# CY8C4A45LQI_483 register map
File version: 0.1
Registers are 32-bit, read-write, no defined reset value unless marked. A register's access mark holds for its fields unless they carry their own. Offsets are from the block's base; [hi:lo] are bit positions; {n}, {i} and the like mark numbered series; 'fields as' and 'values as' point back to an identical list.

## engine_sensor_adc_UABH_B
Base 0x00000000
Same registers: engine_sensor_adc_UABH_A 0x00000000
0x40340000 UAB_UAB_CTRL — Global UAB control
  [31] ENABLED — - 0: UAB IP disabled (put analog in power down, open all switches)?- 1: UAB IP enabled
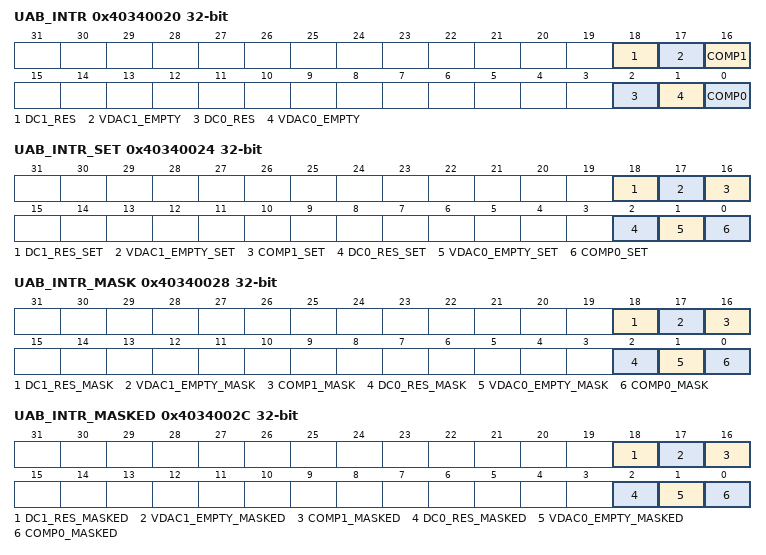
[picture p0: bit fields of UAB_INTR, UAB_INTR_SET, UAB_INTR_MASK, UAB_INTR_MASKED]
0x40340020 UAB_INTR — Interrupt request register
  [18] DC1_RES — Decimator 1 Result Interrupt: hardware sets this interrupt when Decimator 1 writes a new result value in DC1_RES register. Write with '1' to clear bit.
  [17] VDAC1_EMPTY — VDAC 1 Interrupt: hardware sets this interrupt when VDAC 1 next value field is empty. Write with '1' to clear bit.
  [16] COMP1 — Comparator 1 Interrupt: hardware sets this interrupt when comparator 1 triggers. Write with '1' to clear bit.
  [2] DC0_RES — Decimator 0 Result Interrupt: hardware sets this interrupt when Decimator 0 writes a new result value in DC0_RES register. Write with '1' to clear bit.
  [1] VDAC0_EMPTY — VDAC 0 Interrupt: hardware sets this interrupt when VDAC 0 next value field is empty. Write with '1' to clear bit.
  [0] COMP0 — Comparator 0 Interrupt: hardware sets this interrupt when comparator 0 triggers. Write with '1' to clear bit.
0x40340024 UAB_INTR_SET — Interrupt request set register
  [18] DC1_RES_SET — Write with '1' to set corresponding bit in interrupt request register.
  [17] VDAC1_EMPTY_SET — Write with '1' to set corresponding bit in interrupt request register.
  [16] COMP1_SET — Write with '1' to set corresponding bit in interrupt request register.
  [2] DC0_RES_SET — Write with '1' to set corresponding bit in interrupt request register.
  [1] VDAC0_EMPTY_SET — Write with '1' to set corresponding bit in interrupt request register.
  [0] COMP0_SET — Write with '1' to set corresponding bit in interrupt request register.
0x40340028 UAB_INTR_MASK — Interrupt request mask
  [18] DC1_RES_MASK — Mask bit for corresponding bit in interrupt request register.
  [17] VDAC1_EMPTY_MASK — Mask bit for corresponding bit in interrupt request register.
  [16] COMP1_MASK — Mask bit for corresponding bit in interrupt request register.
  [2] DC0_RES_MASK — Mask bit for corresponding bit in interrupt request register.
  [1] VDAC0_EMPTY_MASK — Mask bit for corresponding bit in interrupt request register.
  [0] COMP0_MASK — Mask bit for corresponding bit in interrupt request register.
0x4034002C UAB_INTR_MASKED — Interrupt request masked
  [18] DC1_RES_MASKED ro — Logical and of corresponding request and mask bits.
  [17] VDAC1_EMPTY_MASKED ro — Logical and of corresponding request and mask bits.
  [16] COMP1_MASKED ro — Logical and of corresponding request and mask bits.
  [2] DC0_RES_MASKED ro — Logical and of corresponding request and mask bits.
  [1] VDAC0_EMPTY_MASKED ro — Logical and of corresponding request and mask bits.
  [0] COMP0_MASKED ro — Logical and of corresponding request and mask bits.
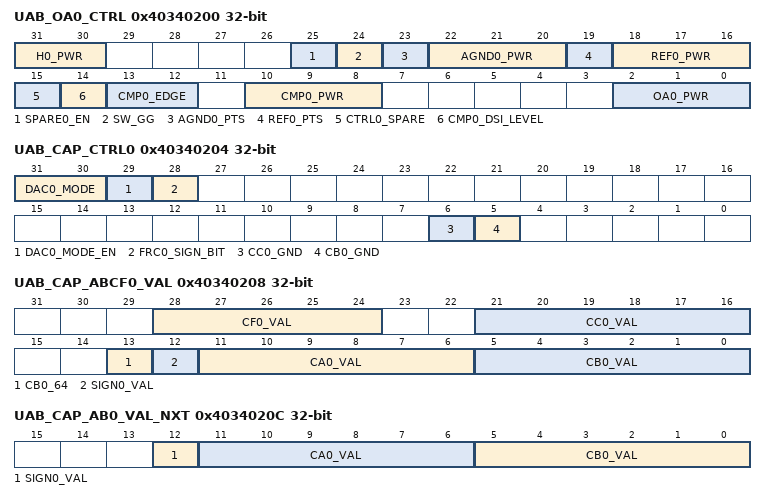
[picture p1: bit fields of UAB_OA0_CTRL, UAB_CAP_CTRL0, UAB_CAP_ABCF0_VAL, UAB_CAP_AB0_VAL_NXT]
0x40340200 UAB_OA0_CTRL — Opamp, comparator, buffer controls
  [31:30] H0_PWR — UAB Half, power profile
    0=NORMAL (Normal, for normal analog clock speeds); 1=ULTRA_LOW (Ultra low power, only allowed for lower analog clock speeds); 2=ULTRA_HIGH (Ultra high performance, for higher analog clock speeds (also ultra high power))
  [25] SPARE0_EN — 1 - Enable spare reference
  [24] SW_GG — Connect outputs of Agnd0 and Agnd1 buffer, one buffer must be off.?This is to drive both UAB halves with the same buffer, so both halves get the same offset noise.
  [23] AGND0_PTS — 1 - Pull Agnd0 buffer output to VDDA
  [22:20] AGND0_PWR — Agnd0 buffer power level
  [19] REF0_PTS — 1- Pull the Reference0 buffer output to VDDA
  [18:16] REF0_PWR — Reference0 buffer power level
  [15] CTRL0_SPARE — Spare bit
  [14] CMP0_DSI_LEVEL — Comparator0 trigger out level : 0=pulse, 1=level
  [13:12] CMP0_EDGE — Comparator0 edge detect for interrupt and trigger
    0=DISABLE (Disabled, no interrupts will be detected); 1=RISING (Rising edge); 2=FALLING (Falling edge); 3=BOTH (Both rising and falling edges)
  [10:8] CMP0_PWR — Comparator0 power level
  [2:0] OA0_PWR — Opamp0 power level
0x40340204 UAB_CAP_CTRL0 — Capacitance controls
  [31:30] DAC0_MODE — DAC mode, this determines the AB Cap Value decoding
    0=UNSIGNED12 (Off or Unsigned 12-bit VDAC, i.e. no AB Cap value decoding.?SIGN1_VAL can be used as Firmware controlled modbit (e.g. to invert the Voltage for a Sign + Magnitude VDAC)); 1=VIRT_SIGNED12 (Virtual signed 12-bits' VDAC. AB Cap value decoding: ?add 0x800 to the 12-bit AB Cap Value (=invert MSB), to convert the lowest signed number 0x800 to the lowest unsigned number 0x000. This is the same as the SAR handles 12-bit 'virtual' signed numbers.); 2=SIGNED13 (Signed 13-bit twos complement. AB Cap value decoding: ?for negative values (SIGN0_VAL=1) the AB Cap values are inverted, the 64th B cap unit is enabled and the Voltage should be inverted.?- Voltage inversion only works if the right clocking waveforms, switch settings and reference voltages are used.?- Enabling the 64th B cap unit adds 1 so that only a AB Cap value inversion is needed to create a true twos complement.)
  [29] DAC0_MODE_EN — 0: SIGN0_VAL can be programmed to be a modbit source?1: SIGN0_VAL is a dedicated sign bit (FW modbit source tied to 0)
  [28] FRC0_SIGN_BIT — Forces the sign bit to be 1 in DAC mode. This is used to achieve ?0 - AGND0 range for unsigned numbers using DAC mode 2
  [6] CC0_GND — Ground unused caps of CC0 array?0: leave unused caps floating?1: ground unused caps (typical when attentuation Cap is used)
  [5] CB0_GND — Ground unused caps of CB0 array?0: leave unused caps floating?1: ground unused caps (typical when attentuation Cap is used, e.g. for VDAC use-case)
0x40340208 UAB_CAP_ABCF0_VAL — Capacitance values for CA0, CB0, CC0 and CF0
  [28:24] CF0_VAL — Cap F0 Value [2..64 is the range in steps of 2]
  [21:16] CC0_VAL — Cap C0 Value
  [13] CB0_64 — Enable 64th Cap of CB0 array. In DAC mode the FW setting is overridden by the hardware based on DAC_MODE setting.?1 - Enables the 64th cap. This will also set CB0_val[5:0] to be 6'h3F
  [12] SIGN0_VAL — Sign bit Value, when used in DAC_MODE, otherwise Firmware modbit.?In DAC_MODE the modbit should be used to invert the voltage on the AB Caps for the negative DAC values.
  [11:6] CA0_VAL — Cap A0 Value, in DAC_MODE 1 and 2 this value is decoded
  [5:0] CB0_VAL — Cap B0 Value, in DAC_MODE 1 and 2 this value is decoded
0x4034020C UAB_CAP_AB0_VAL_NXT — Next capacitance values for CA0 and CB0
  [12] SIGN0_VAL — Sign bit Value
  [11:6] CA0_VAL — Cap A0 Value
  [5:0] CB0_VAL — Cap B0 Value
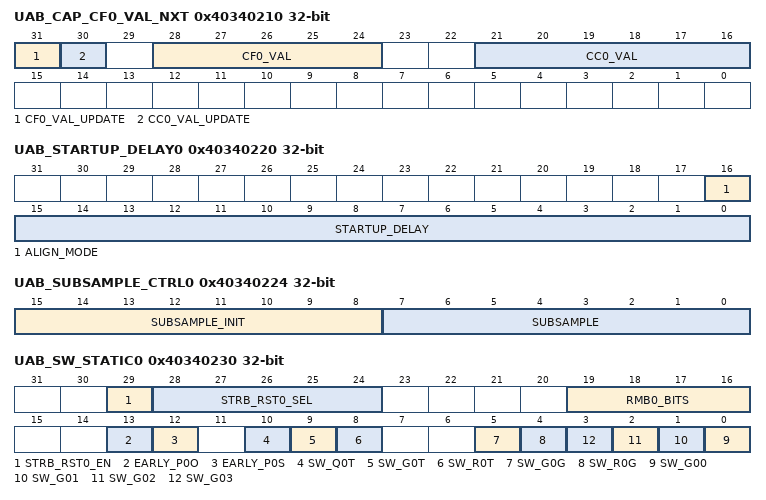
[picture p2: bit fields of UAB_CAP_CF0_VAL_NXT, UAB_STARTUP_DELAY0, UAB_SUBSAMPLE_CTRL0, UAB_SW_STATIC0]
0x40340210 UAB_CAP_CF0_VAL_NXT — Next capacitance values for CC0 and CF0
  [31] CF0_VAL_UPDATE — 1 - Update the CF0 cap value with CAP_CF0_VAL_NXT.CF0_VAL
  [30] CC0_VAL_UPDATE — 1 - Update the CC0 cap value with CAP_CC0_VAL_NXT.CC0_VAL
  [28:24] CF0_VAL — Cap F0 Value
  [21:16] CC0_VAL — Cap C0 Value
0x40340220 UAB_STARTUP_DELAY0 — Startup delay
  [16] ALIGN_MODE — 0 - STARTUP_DELAY is number of clk_hf clocks to delay the UAB clock after a SAR Trigger for UAB-SAR alignment in scheduled mode?1 - STARTUP_DELAY is number of clk_hf clocks to delay UAB trigger to SAR for UAB-SAR alignment in unscheduled mode
  [15:0] STARTUP_DELAY — Startup delay to synchronize the UAB-SAR interface. The usage and meaning of this field depends on the value of the ALIGN_MODE bit (below). A value of 0 disables this function.
0x40340224 UAB_SUBSAMPLE_CTRL0 — Subsample control
  [15:8] SUBSAMPLE_INIT — Initial value of the subsampling down counter. Before this UAB half is running the firmware can write to this field the initial value of the subsample down counter. It is recommend that the following is true for the initial value SUBSAMPLE_INIT<=SUBSAMPLE, however this is not a requirement. Writing a bigger value can be used to postpone the very first Valid output.
  [7:0] SUBSAMPLE — Subsampling: suppress Valid output during the first SUBSAMPLE analog clock periods. Only allow Valid output in the last of the SUBSAMPLE+1 analog clock periods.?A value of 0 will not suppress Valid output.
0x40340230 UAB_SW_STATIC0 — Static switches for half 0 of the UAB
  [29] STRB_RST0_EN — Enable VDAC strobe or UAB analog-reset:?0: Use selected source as VDAC strobe for next CA0 and CB0 values?1: Use selected source as Analog-reset (discharge all Caps)
  [28:24] STRB_RST0_SEL — Select source either for VDAC strobe or analog-reset to discharge all Caps (Delsig Modulator use-case)?0 = Decimator0 half 0 analog-reset output?1 = Decimator0 half 1 analog-reset output?2 = Decimator1 half 0 analog-reset output?3 = Decimator1 half 1 analog-reset output?4 = Decimator2 half 0 analog-reset output?5 = Decimator2 half 1 analog-reset output?6 = Decimator3 half 0 analog-reset output?7 = Decimator3 half 1 analog-reset output?8-31 = generic trigger input 0-23?For PASS4B only values 0-1 and 8-13 are legal.
  [19:16] RMB0_BITS — Risk mitigation bits (To be defined if they are used)
  [13] EARLY_P0O — OUT0 to VOUT0 switch timing: 0=Regular, 1=Early
  [12] EARLY_P0S — OUT0 to Sum0 switch timing: 0=Regular, 1=Early
  [10] SW_Q0T — OUT1 to cmp0.vminus (Threshold)
  [9] SW_G0T — AGND0 to cmp0.vminus (Threshold)
  [8] SW_R0T — REF0 to cmp0.vminus (Threshold)
  [5] SW_G0G — AGND0 to OA0.vplus (AG0)
  [4] SW_R0G — REF0 to OA0.vplus (AG0)
  [n] SW_G{n:02} (n=0..3) — VIN{n:02} to OA0.vplus (AG0)
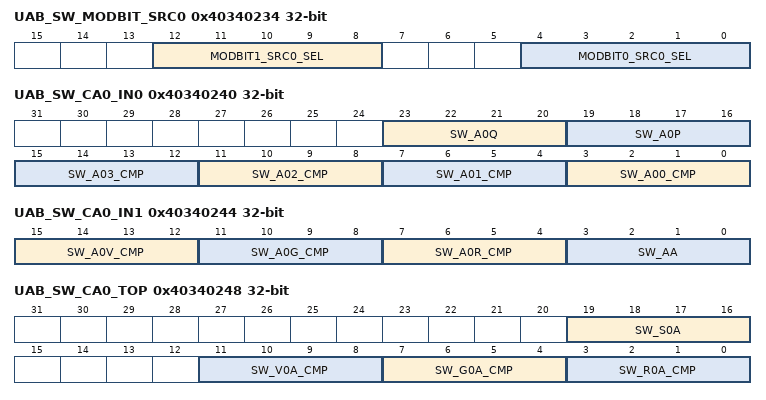
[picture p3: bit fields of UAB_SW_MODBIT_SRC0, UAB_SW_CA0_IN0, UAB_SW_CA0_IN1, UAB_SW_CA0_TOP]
0x40340234 UAB_SW_MODBIT_SRC0 — Select source of Modbit for A,B and C branches of half 0
  [12:8] MODBIT1_SRC0_SEL — Select source of modbit for C branch?0=UAB0 half 0 comparator output?1=UAB0 half 1 comparator output?2=UAB1 half 0 comparator output?3=UAB1 half 1 comparator output?4=UAB2 half 0 comparator output?5=UAB2 half 1 comparator output?6=UAB3 half 0 comparator output?7=UAB3 half 1 comparator output?8-30 = generic trigger inputs 0-22?31=SIGN0_VAL, also used as Firmware modbit. ?For PASS4B only values 0-1 and 8-13 and 31 are legal.
  [4:0] MODBIT0_SRC0_SEL — Select source of modbit for A & B branches?0=UAB0 half 0 comparator output?1=UAB0 half 1 comparator output?2=UAB1 half 0 comparator output?3=UAB1 half 1 comparator output?4=UAB2 half 0 comparator output?5=UAB2 half 1 comparator output?6=UAB3 half 0 comparator output?7=UAB3 half 1 comparator output?8-30 = generic trigger inputs 0-22?31=SIGN0_VAL, also used as Firmware modbit. ?For PASS4B only values 0-1 and 8-13 and 31 are legal.
0x40340240 UAB_SW_CA0_IN0 — Cap A0 input switches set 0
  [23:20] SW_A0Q — OUT1 to Cap A0 input
  [19:16] SW_A0P — OUT0 to Cap A0 input
  [4n+3:4n] SW_A{n:02}_CMP (n=0..3) — VIN{n:02} to Cap A0 input, allows for modbit control
0x40340244 UAB_SW_CA0_IN1 — Cap A0 input switches set 1
  [15:12] SW_A0V_CMP — VSS to Cap A0 input, allows for modbit control
  [11:8] SW_A0G_CMP — AGND0 to Cap A0 input, allows for modbit control
  [7:4] SW_A0R_CMP — REF0 to Cap A0 input, allows for modbit control
  [3:0] SW_AA — Cap A0 input to Cap A1 input?(Note: In the UAB design this is the called AM switch)
0x40340248 UAB_SW_CA0_TOP — Cap A0 top plate switches
  [19:16] SW_S0A — Cap A0 top plate to SUM0
  [11:8] SW_V0A_CMP — Cap A0 top plate to VSS, allows for modbit control
  [7:4] SW_G0A_CMP — Cap A0 top plate to AGND0, allows for modbit control
  [3:0] SW_R0A_CMP — Cap A0 top plate to REF0, allows for modbit control
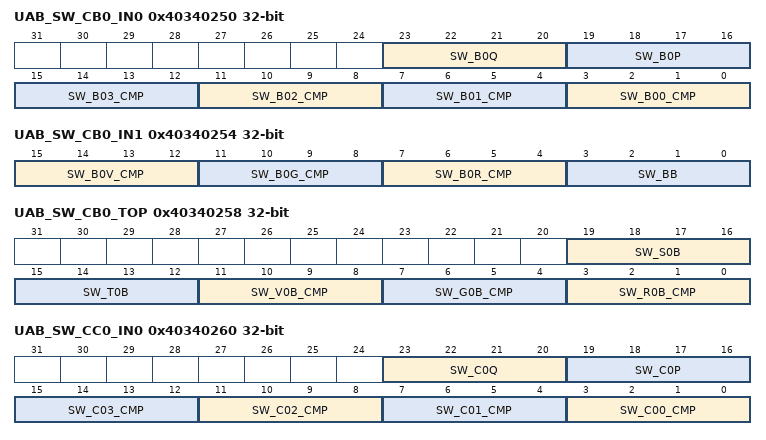
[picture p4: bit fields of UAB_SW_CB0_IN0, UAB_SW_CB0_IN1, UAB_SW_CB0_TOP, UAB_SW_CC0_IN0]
0x40340250 UAB_SW_CB0_IN0 — Cap B0 input switches set 0
  [23:20] SW_B0Q — OUT1 to Cap B0 input
  [19:16] SW_B0P — OUT0 to Cap B0 input
  [4n+3:4n] SW_B{n:02}_CMP (n=0..3) — VIN{n:02} to Cap B0 input, allows for modbit control
0x40340254 UAB_SW_CB0_IN1 — Cap B0 input switches set 1
  [15:12] SW_B0V_CMP — VSS to Cap B0 input, allows for modbit control
  [11:8] SW_B0G_CMP — AGND0 to Cap B0 input, allows for modbit control
  [7:4] SW_B0R_CMP — REF0 to Cap B0 input, allows for modbit control
  [3:0] SW_BB — Cap B0 input to Cap B1 input?(Note: In the UAB design this is called the BM switch)
0x40340258 UAB_SW_CB0_TOP — Cap A0 top plate switches
  [19:16] SW_S0B — Cap B0 top plate to SUM0
  [15:12] SW_T0B — Cap B0 top plate Trim/Attenuation bypass
  [11:8] SW_V0B_CMP — Cap B0 top plate to VSS, allows for modbit control
  [7:4] SW_G0B_CMP — Cap B0 top plate to AGND0, allows for modbit control
  [3:0] SW_R0B_CMP — Cap B0 top plate to REF0, allows for modbit control
0x40340260 UAB_SW_CC0_IN0 — Cap C0 input switches set 0
  [23:20] SW_C0Q — OUT1 to Cap C0 input
  [19:16] SW_C0P — OUT0 to Cap C0 input
  [4n+3:4n] SW_C{n:02}_CMP (n=0..3) — VIN{n:02} to Cap C0 input, allows for modbit control
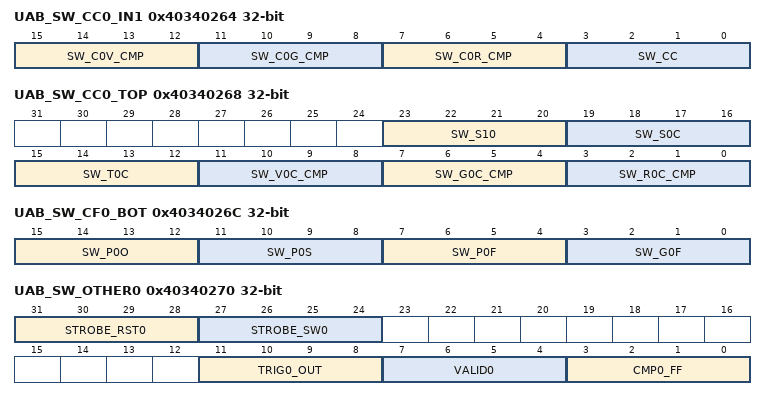
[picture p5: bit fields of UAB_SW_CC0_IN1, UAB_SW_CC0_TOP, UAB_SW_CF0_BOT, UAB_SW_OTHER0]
0x40340264 UAB_SW_CC0_IN1 — Cap C0 input switches set 1
  [15:12] SW_C0V_CMP — VSS to Cap C0 input, allows for modbit control
  [11:8] SW_C0G_CMP — AGND0 to Cap C0 input, allows for modbit control
  [7:4] SW_C0R_CMP — REF0 to Cap C0 input, allows for modbit control
  [3:0] SW_CC — Cap C0 input to Cap C1 input?(Note: In the UAB design this is called the CM switch)
0x40340268 UAB_SW_CC0_TOP — Cap A0 top plate switches
  [23:20] SW_S10 — Cap C0 top plate to SUM1
  [19:16] SW_S0C — Cap C0 top plate to SUM0
  [15:12] SW_T0C — Cap C0 top plate Trim/Attenuation bypass
  [11:8] SW_V0C_CMP — Cap C0 top plate to VSS, allows for modbit control
  [7:4] SW_G0C_CMP — Cap C0 top plate to AGND0, allows for modbit control
  [3:0] SW_R0C_CMP — Cap C0 top plate to REF0, allows for modbit control
0x4034026C UAB_SW_CF0_BOT — Cap F0 bottom plate and output switches
  [15:12] SW_P0O — OUT0 to VOUT0
  [11:8] SW_P0S — Cap F bypass, OUT0 to SUM0
  [7:4] SW_P0F — Cap F0 bottom plate to OUT0
  [3:0] SW_G0F — Cap F0 bottom plate to AGND0
0x40340270 UAB_SW_OTHER0 — Other clocked controls
  [31:28] STROBE_RST0 — Use the positive edge of the selected clocking waveform to synchronize: ? STRB_RST0_EN=0: Capacitor Value update (Capacitor Strobe)? STRB_RST0_EN=1: UAB analog-reset update?Set to 0 to disable both functions. Result undefined for value 15.
  [27:24] STROBE_SW0 — Strobe for dsi_sw_ctrl (modbit) update, dsi_sw_ctrl updates in sync with posedge of this wave. To disable set to 0. To enable update anytime use 15.
  [11:8] TRIG0_OUT — Trigger output (for other UABs or SAR)
  [7:4] VALID0 — Valid0, output flag to indicated that VOUT0 is valid. The Valid output can be suppressed due to sub-sampling. Note that when sub-sampling is used this clocking waveform is used to decrement the counter (decrement is aligned with the positive edge of this clocking waveform).
  [3:0] CMP0_FF — Clock for Flip-Flop after Comparator 0
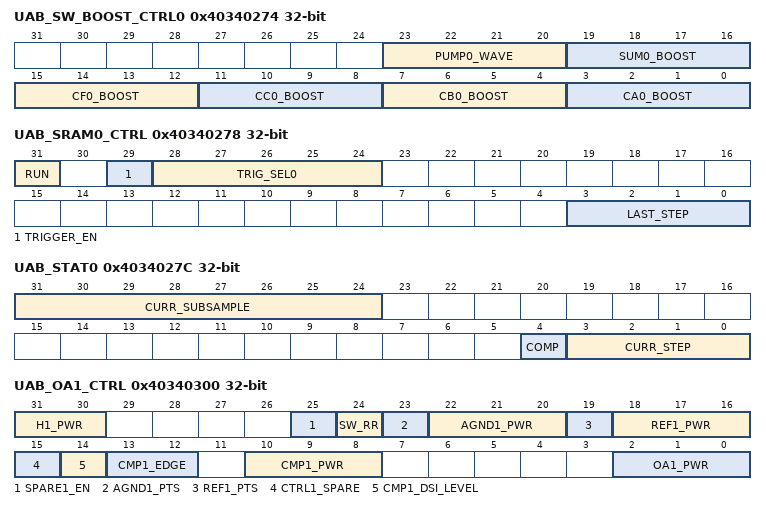
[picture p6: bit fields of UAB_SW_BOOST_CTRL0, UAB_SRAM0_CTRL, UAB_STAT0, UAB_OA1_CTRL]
0x40340274 UAB_SW_BOOST_CTRL0 — Bootstrap clock control
  [23:20] PUMP0_WAVE — Clock for pump in half0
  [19:16] SUM0_BOOST — Clock for boot strap master in Summing node branch
  [15:12] CF0_BOOST — Clock for boot strap master in F branch
  [11:8] CC0_BOOST — Clock for boot strap master in C branch
  [7:4] CB0_BOOST — Clock for boot strap master in B branch
  [3:0] CA0_BOOST — Clock for boot strap master in A branch
0x40340278 UAB_SRAM0_CTRL — SRAM programmed size
  [31] RUN — Set to start executing the waveform (may need to wait for a trigger). Clear to stop this UAB half. When RUN=0 all dynamic switches are forced open.
  [29] TRIGGER_EN — Enable input trigger:?0: Ignore triggers, start running immediately after setting RUN bit?1: After RUN bit is set wait for a positive edge on the selected trigger input
  [28:24] TRIG_SEL0 — input Trigger select?0=UAB0 half 0 trigger output?1=UAB0 half 1 trigger output?2=UAB1 half 0 trigger output?3=UAB1 half 1 trigger output?4=UAB2 half 0 trigger output?5=UAB2 half 1 trigger output?6=UAB3 half 0 trigger output?7=UAB3 half 1 trigger output?8-30 = generic trigger inputs 0-22?31=SAR trigger output?For PASS4B only values 0-1 and 8-13 and 31 are legal.
  [3:0] LAST_STEP — Last step of wave programmed in the SRAM
0x4034027C UAB_STAT0 — Status Current SRAM counter and comparator
  [31:24] CURR_SUBSAMPLE ro — Current value of the subsampling down counter. The Valid is suppressed when SUBSAMPLE_CUR!=0.
  [4] COMP ro — Current comparator status
  [3:0] CURR_STEP ro — Current step executed from the SRAM
{0x40340280+4i} UAB_SRAM{i:02} (i=0..9) — Waveform SRAM for half 0 of the UAB
  [15:0] WAVE_STEP — one step of the clocking waveform sequence
0x403402A8 UAB_SRAM010 — Waveform SRAM for half 0 of the UAB
  [15:0] WAVE_STEP — one step of the clocking waveform sequence
0x403402AC UAB_SRAM011 — Waveform SRAM for half 0 of the UAB
  [15:0] WAVE_STEP — one step of the clocking waveform sequence
0x403402B0 UAB_SRAM012 — Waveform SRAM for half 0 of the UAB
  [15:0] WAVE_STEP — one step of the clocking waveform sequence
0x403402B4 UAB_SRAM013 — Waveform SRAM for half 0 of the UAB
  [15:0] WAVE_STEP — one step of the clocking waveform sequence
0x403402B8 UAB_SRAM014 — Waveform SRAM for half 0 of the UAB
  [15:0] WAVE_STEP — one step of the clocking waveform sequence
0x403402BC UAB_SRAM015 — Waveform SRAM for half 0 of the UAB
  [15:0] WAVE_STEP — one step of the clocking waveform sequence
0x40340300 UAB_OA1_CTRL — Opamp, comparator, buffer controls
  [31:30] H1_PWR — UAB Half, power profile
    values as UAB_OA0_CTRL.H0_PWR
  [25] SPARE1_EN — 1 - Enable the spare reference
  [24] SW_RR — Connect outputs of Reference0 and Reference1 buffer, one buffer must be off.?This is to drive both UAB halves with the same buffer, so both halves get the same offset noise.
  [23] AGND1_PTS — 1- Pull the Agnd1 buffer output to VDDA
  [22:20] AGND1_PWR — Agnd1 buffer power
  [19] REF1_PTS — 1- Pull the Reference1 buffer output to VDDA
  [18:16] REF1_PWR — Reference1 buffer power
  [15] CTRL1_SPARE — Spare bit
  [14] CMP1_DSI_LEVEL — Comparator trigger out level : 0=pulse, 1=level
  [13:12] CMP1_EDGE — Comparator1 edge detect for interrupt and trigger
    values as UAB_OA0_CTRL.CMP0_EDGE
  [10:8] CMP1_PWR — Comparator1 power level
  [2:0] OA1_PWR — Opamp1 power level
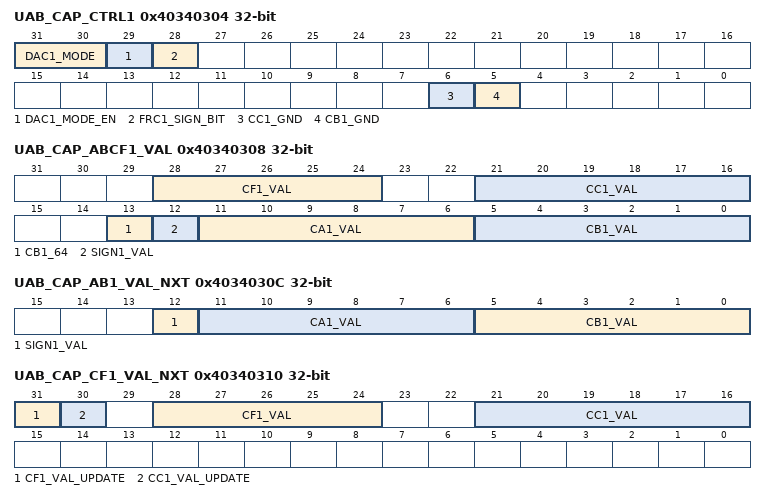
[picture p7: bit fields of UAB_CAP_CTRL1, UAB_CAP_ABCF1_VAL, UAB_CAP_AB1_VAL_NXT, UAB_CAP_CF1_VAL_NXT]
0x40340304 UAB_CAP_CTRL1 — Capacitance controls
  [31:30] DAC1_MODE — DAC mode, this determines the AB Cap Value decoding
    0=UNSIGNED12 (Off or Unsigned 12-bit VDAC, i.e. no AB Cap value decoding.?SIGN1_VAL can be used as Firmware controlled modbit (e.g. to invert the Voltage for a Sign + Magnitude VDAC)); 1=VIRT_SIGNED12 (Virtual signed 12-bits' VDAC. AB Cap value decoding: ?add 0x800 to the 12-bit AB Cap Value (=invert MSB), to convert the lowest signed number 0x800 to the lowest unsigned number 0x000. This is the same as the SAR handles 12-bit 'virtual' signed numbers.); 2=SIGNED13 (Signed 13-bit twos complement. AB Cap value decoding: ?for negative values (SIGN1_VAL=1) the AB Cap values are inverted, the 64th B cap unit is enabled and the Voltage should be inverted.?- Voltage inversion only works if the right clocking waveforms, switch settings and reference voltages are used.?- Enabling the 64th B cap unit adds 1 so that only a AB Cap value inversion is needed to create a true twos complement. .)
  [29] DAC1_MODE_EN — 1: SIGN1_VAL is dedicated sign bit (FW modbit source tied to 0) 0: SIGN1_VAL can be programmed to be a modbit source
  [28] FRC1_SIGN_BIT — Forces the sign bit to be 1 in DAC mode. This is used to achieve ?0 - AGND1 range for unsigned numbers using DAC mode 2
  [6] CC1_GND — Ground unused caps of CC1 array?0: leave unused caps floating?1: ground unused caps (typical when attentuation Cap is used)
  [5] CB1_GND — Ground unused caps of CB1 array?0: leave unused caps floating?1: ground unused caps (typical when attentuation Cap is used, e.g. for VDAC use-case)
0x40340308 UAB_CAP_ABCF1_VAL — Capacitance values for CA1, CB1, CC1 and CF1
  [28:24] CF1_VAL — Cap F1 Value
  [21:16] CC1_VAL — Cap C1 Value
  [13] CB1_64 — Enable 64th Cap of CB1 array. In DAC mode the FW setting is overridden by the hardware based on DAC_MODE setting. 1 - Enables the 64th cap. This will also set CB1_val[5:0] to be 6'h3F
  [12] SIGN1_VAL — Sign bit Value, when used in DAC_MODE, otherwise Firmware modbit.?In DAC_MODE the modbit should be used to invert the voltage on the AB Caps for the negative DAC values.
  [11:6] CA1_VAL — Cap A1 Value, in DAC_MODE 1 and 2 this value is decoded
  [5:0] CB1_VAL — Cap B1 Value, in DAC_MODE 1 and 2 this value is decoded
0x4034030C UAB_CAP_AB1_VAL_NXT — Next capacitance values for CA1 and CB1
  [12] SIGN1_VAL — Sign bit Value
  [11:6] CA1_VAL — Cap A1 Value
  [5:0] CB1_VAL — Cap B1 Value
0x40340310 UAB_CAP_CF1_VAL_NXT — Next capacitance values for CC1 and CF1
  [31] CF1_VAL_UPDATE — 1 - Update the CF1 cap value with CAP_CF1_VAL_NXT.CF1_VAL
  [30] CC1_VAL_UPDATE — 1 - Update the CC1 cap value with CAP_CC1_VAL_NXT.CC1_VAL
  [28:24] CF1_VAL — Cap F1 Value
  [21:16] CC1_VAL — Cap C1 Value
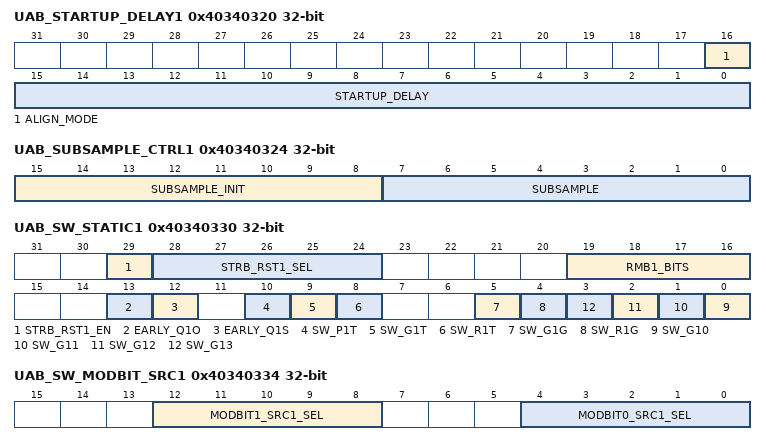
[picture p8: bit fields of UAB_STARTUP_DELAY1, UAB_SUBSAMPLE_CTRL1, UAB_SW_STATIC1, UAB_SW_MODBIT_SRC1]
0x40340320 UAB_STARTUP_DELAY1 — Startup delay
  fields as UAB_STARTUP_DELAY0
0x40340324 UAB_SUBSAMPLE_CTRL1 — Subsample control
  fields as UAB_SUBSAMPLE_CTRL0
0x40340330 UAB_SW_STATIC1 — Static switches for half 1 of the UAB
  [29] STRB_RST1_EN — Enable VDAC strobe or UAB analog-reset:?0: Use selected source as VDAC strobe for next CA1 and CB1 values?1: Use selected source as Analog-reset (discharge all Caps)
  [28:24] STRB_RST1_SEL — Select source either for VDAC strobe or analog-reset to discharge all Caps (Delsig Modulator use-case)?0 = Decimator0 half 0 analog-reset output?1 = Decimator0 half 1 analog-reset output?2 = Decimator1 half 0 analog-reset output?3 = Decimator1 half 1 analog-reset output?4 = Decimator2 half 0 analog-reset output?5 = Decimator2 half 1 analog-reset output?6 = Decimator3 half 0 analog-reset output?7 = Decimator3 half 1 analog-reset output?8-31 = generic trigger input 0-23?For PASS4B only values 0-1 and 8-13 are legal.
  [19:16] RMB1_BITS — Risk mitigation bits (To be defined if they are used)
  [13] EARLY_Q1O — OUT1 to VOUT1 switch timing: 0=Regular, 1=Early
  [12] EARLY_Q1S — OUT1 to Sum1 switch timing: 0=Regular, 1=Early
  [10] SW_P1T — OUT0 to cmp1.vminus (Threshold)
  [9] SW_G1T — AGND1 to cmp1.vminus (Threshold)
  [8] SW_R1T — REF1 to cmp1.vminus (Threshold)
  [5] SW_G1G — AGND1 to OA1.vplus (AG1)
  [4] SW_R1G — REF1 to OA1.vplus (AG1)
  [n-10] SW_G{n} (n=10..13) — VIN{n} to OA1.vplus (AG1)
0x40340334 UAB_SW_MODBIT_SRC1 — Select source of Modbit for A,B and C branches of half 1
  [12:8] MODBIT1_SRC1_SEL — Select source of modbit for C branch?0=UAB0 half 0 comparator output?1=UAB0 half 1 comparator output?2=UAB1 half 0 comparator output?3=UAB1 half 1 comparator output?4=UAB2 half 0 comparator output?5=UAB2 half 1 comparator output?6=UAB3 half 0 comparator output?7=UAB3 half 1 comparator output?8-30 = generic trigger inputs 0-22?31=SIGN1_VAL, also used as Firmware modbit.?For PASS4B only values 0-1 and 8-11 and 31 are legal.
  [4:0] MODBIT0_SRC1_SEL — Select source of modbit for A & B branches?0=UAB0 half 0 comparator output?1=UAB0 half 1 comparator output?2=UAB1 half 0 comparator output?3=UAB1 half 1 comparator output?4=UAB2 half 0 comparator output?5=UAB2 half 1 comparator output?6=UAB3 half 0 comparator output?7=UAB3 half 1 comparator output?8-30 = generic trigger inputs 0-22?31=SIGN1_VAL, also used as Firmware modbit.?For PASS4B only values 0-1 and 8-13 and 31 are legal.
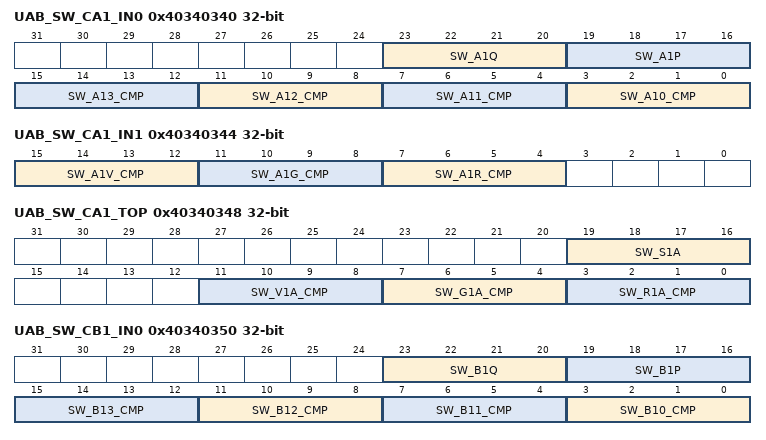
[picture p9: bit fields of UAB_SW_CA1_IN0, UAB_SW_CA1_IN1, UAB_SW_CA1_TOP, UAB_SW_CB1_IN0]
0x40340340 UAB_SW_CA1_IN0 — Cap A1 input switches set 0
  [23:20] SW_A1Q — OUT0 to Cap A1 input
  [19:16] SW_A1P — OUT1 to Cap A1 input
  [4n-37:4n-40] SW_A{n}_CMP (n=10..13) — VIN{n} to Cap A1 input, allows for modbit control
0x40340344 UAB_SW_CA1_IN1 — Cap A1 input switches set 1
  [15:12] SW_A1V_CMP — VSS to Cap A1 input, allows for modbit control
  [11:8] SW_A1G_CMP — AGND1 to Cap A1 input, allows for modbit control
  [7:4] SW_A1R_CMP — REF1 to Cap A1 input, allows for modbit control
0x40340348 UAB_SW_CA1_TOP — Cap A1 top plate switches
  [19:16] SW_S1A — Cap A1 top plate to SUM1
  [11:8] SW_V1A_CMP — Cap A1 top plate to VSS, allows for modbit control
  [7:4] SW_G1A_CMP — Cap A1 top plate to AGND1, allows for modbit control
  [3:0] SW_R1A_CMP — Cap A1 top plate to REF1, allows for modbit control
0x40340350 UAB_SW_CB1_IN0 — Cap B1 input switches set 0
  [23:20] SW_B1Q — OUT0 to Cap B1 input
  [19:16] SW_B1P — OUT1 to Cap B1 input
  [4n-37:4n-40] SW_B{n}_CMP (n=10..13) — VIN{n} to Cap B1 input, allows for modbit control
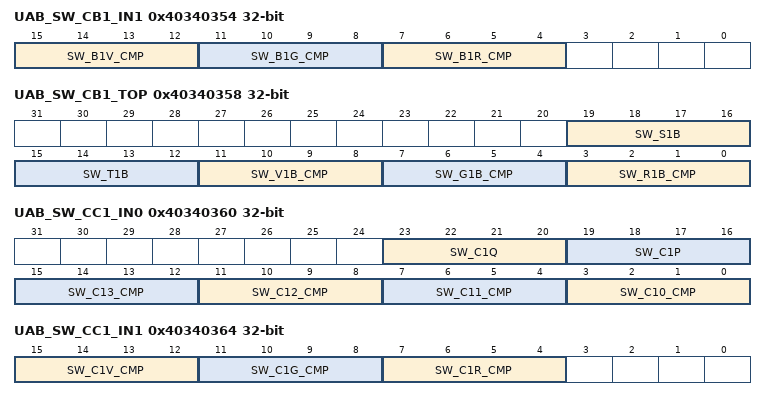
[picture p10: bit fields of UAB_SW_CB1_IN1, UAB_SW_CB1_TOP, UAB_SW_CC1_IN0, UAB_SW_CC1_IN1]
0x40340354 UAB_SW_CB1_IN1 — Cap B1 input switches set 1
  [15:12] SW_B1V_CMP — VSS to Cap B1 input, allows for modbit control
  [11:8] SW_B1G_CMP — AGND1 to Cap B1 input, allows for modbit control
  [7:4] SW_B1R_CMP — REF1 to Cap B1 input, allows for modbit control
0x40340358 UAB_SW_CB1_TOP — Cap A1 top plate switches
  [19:16] SW_S1B — Cap B1 top plate to SUM1
  [15:12] SW_T1B — Cap B1 top plate Trim/Attenuation bypass
  [11:8] SW_V1B_CMP — Cap B1 top plate to VSS, allows for modbit control
  [7:4] SW_G1B_CMP — Cap B1 top plate to AGND1, allows for modbit control
  [3:0] SW_R1B_CMP — Cap B1 top plate to REF1, allows for modbit control
0x40340360 UAB_SW_CC1_IN0 — Cap C1 input switches set 0
  [23:20] SW_C1Q — OUT0 to Cap C1 input
  [19:16] SW_C1P — OUT1 to Cap C1 input
  [4n-37:4n-40] SW_C{n}_CMP (n=10..13) — VIN{n} to Cap C1 input, allows for modbit control
0x40340364 UAB_SW_CC1_IN1 — Cap C1 input switches set 1
  [15:12] SW_C1V_CMP — VSS to Cap C1 input, allows for modbit control
  [11:8] SW_C1G_CMP — AGND1 to Cap C1 input, allows for modbit control
  [7:4] SW_C1R_CMP — REF1 to Cap C1 input, allows for modbit control
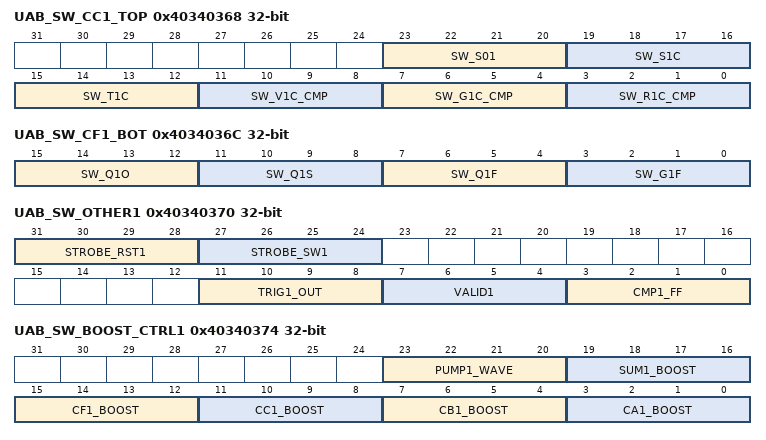
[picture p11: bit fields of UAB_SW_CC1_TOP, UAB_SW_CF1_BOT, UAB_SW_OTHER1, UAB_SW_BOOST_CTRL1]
0x40340368 UAB_SW_CC1_TOP — Cap A1 top plate switches
  [23:20] SW_S01 — Cap C1 top plate to SUM0
  [19:16] SW_S1C — Cap C1 top plate to SUM1
  [15:12] SW_T1C — Cap C1 top plate Trim/Attenuation bypass
  [11:8] SW_V1C_CMP — Cap C1 top plate to VSS, allows for modbit control
  [7:4] SW_G1C_CMP — Cap C1 top plate to AGND1, allows for modbit control
  [3:0] SW_R1C_CMP — Cap C1 top plate to REF1, allows for modbit control
0x4034036C UAB_SW_CF1_BOT — Cap F1 bottom plate and output switches
  [15:12] SW_Q1O — OUT1 to VOUT1
  [11:8] SW_Q1S — Cap F bypass, OUT1 to SUM1
  [7:4] SW_Q1F — Cap F1 bottom plate to OUT1
  [3:0] SW_G1F — Cap F1 bottom plate to AGND1
0x40340370 UAB_SW_OTHER1 — Other clocked controls
  [31:28] STROBE_RST1 — Use the positive edge of the selected clocking waveform to synchronize: ? STRB_RST0_EN=0: Capacitor Value update (Capacitor Strobe)? STRB_RST0_EN=1: UAB analog-reset update?Set to 0 to disable both functions. Result undefined for value 15.
  [27:24] STROBE_SW1 — Strobe for dsi_sw_ctrl (modbit) update, dsi_sw_ctrl updates in sync with posedge of this wave. To disable set to 0. To enable update anytime use 15.
  [11:8] TRIG1_OUT — Trigger output (for other UABs or SAR)
  [7:4] VALID1 — Valid1, output flag to indicated that VOUT1 is valid. The Valid output can be suppressed due to sub-sampling. Note that when sub-sampling is used this clocking waveform is used to decrement the counter (decrement is aligned with the positive edge of this clocking waveform).
  [3:0] CMP1_FF — Clock for Flip-Flop after Comparator 1
0x40340374 UAB_SW_BOOST_CTRL1 — Bootstrap clock control
  [23:20] PUMP1_WAVE — Clock for pump in half1
  [19:16] SUM1_BOOST — Clock for boot strap master in Summing node branch
  [15:12] CF1_BOOST — Clock for boot strap master in F branch
  [11:8] CC1_BOOST — Clock for boot strap master in C branch
  [7:4] CB1_BOOST — Clock for boot strap master in B branch
  [3:0] CA1_BOOST — Clock for boot strap master in A branch
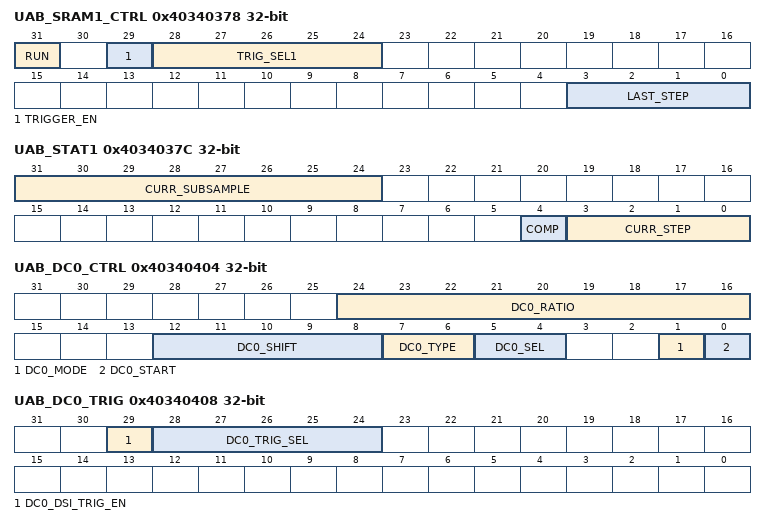
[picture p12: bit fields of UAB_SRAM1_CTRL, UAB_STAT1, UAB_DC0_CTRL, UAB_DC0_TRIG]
0x40340378 UAB_SRAM1_CTRL — SRAM programmed size
  [31] RUN — Set to start executing the waveform (may need to wait for a trigger). Clear to stop this UAB half. When RUN=0 all dynamic switches are forced open.
  [29] TRIGGER_EN — Enable input trigger:?0: Ignore triggers, start running immediately after setting RUN bit?1: After RUN bit is set wait for a positive edge on the selected trigger input
  [28:24] TRIG_SEL1 — Trigger select?0=UAB0 half 0 trigger output?1=UAB0 half 1 trigger output?2=UAB1 half 0 trigger output?3=UAB1 half 1 trigger output?4=UAB2 half 0 trigger output?5=UAB2 half 1 trigger output?6=UAB3 half 0 trigger output?7=UAB3 half 1 trigger output?8-30 = generic trigger inputs 0-22?31=SAR trigger output?For PASS4B only values 0-1 and 8-13 and 31 are legal.
  [3:0] LAST_STEP — Last step of wave programmed in the SRAM
0x4034037C UAB_STAT1 — Status Current SRAM counter and comparator
  fields as UAB_STAT0
0x40340380 UAB_SRAM10 — Waveform SRAM for half 1 of the UAB
  [15:0] WAVE_STEP — one step of the clocking waveform sequence
0x40340384 UAB_SRAM11 — Waveform SRAM for half 1 of the UAB
  [15:0] WAVE_STEP — one step of the clocking waveform sequence
0x40340388 UAB_SRAM12 — Waveform SRAM for half 1 of the UAB
  [15:0] WAVE_STEP — one step of the clocking waveform sequence
0x4034038C UAB_SRAM13 — Waveform SRAM for half 1 of the UAB
  [15:0] WAVE_STEP — one step of the clocking waveform sequence
0x40340390 UAB_SRAM14 — Waveform SRAM for half 1 of the UAB
  [15:0] WAVE_STEP — one step of the clocking waveform sequence
{0x40340358+4i} UAB_SRAM{i} (i=15..19) — Waveform SRAM for half 1 of the UAB
  [15:0] WAVE_STEP — one step of the clocking waveform sequence
{0x403401F0+4i} UAB_SRAM{i} (i=110..115) — Waveform SRAM for half 1 of the UAB
  [15:0] WAVE_STEP — one step of the clocking waveform sequence
0x40340400 UAB_DECM_CTRL — Global decimator control
  [31] ENABLED — - 0: Decimator disabled (independent of UAB)?- 1: Decimator enabled (independent of UAB)
0x40340404 UAB_DC0_CTRL — decimator0 control
  [24:16] DC0_RATIO — decimation ratio = DC0_RATIO+1, range 1..512
  [12:8] DC0_SHIFT — shift the result right by specified amount, legal range 0..16
  [7:6] DC0_TYPE — decimator type (filter order)
    0=SINC1 (first order); 1=SINC2 (second order); 2=SINC3 (third order, this uses half of decimator1, therefore cannot be combined with dc1_mode SINC2)
  [5:4] DC0_SEL — Source select
    0=UAB_H0 (Comparator output from Half0 of this UAB); 1=UAB_H1 (Comparator output from Half1 of this UAB); 2=DSI0; 3=DSI1
  [1] DC0_MODE — Operation mode?0: Incremental (one-shot) operation?1: Continuous operation
  [0] DC0_START — Start decimator, in incremental mode, this bit is cleared by HW when done. If DSI trigger enable is set then only start after a DSI trigger.
0x40340408 UAB_DC0_TRIG — decimator0 trigger control
  [29] DC0_DSI_TRIG_EN — Decimator DSI trigger input Enable?0: Ignore decimator DSI trigger input?1: Wait for positive edge on selected DSI trigger input
  [28:24] DC0_TRIG_SEL — Trigger select?0=UAB0 half 0 trigger output?1=UAB0 half 1 trigger output?2=UAB1 half 0 trigger output?3=UAB1 half 1 trigger output?4=UAB2 half 0 trigger output?5=UAB2 half 1 trigger output?6=UAB3 half 0 trigger output?7=UAB3 half 1 trigger output?8-30 = generic trigger inputs 0-22?31=SAR trigger output?For PASS4B only values 0-1 and 8-11 and 31 are legal.
0x4034040C UAB_DC0_OVR — decimator 0 overflow control
  [4:0] DC0_OVR_CORR_LOC — Bit location for overflow correction. This should be set to FILTER_ORDER*log2(DC0_RATIO)
0x40340410 UAB_DC0_A0 — decimator0 accumulator 0
  [31:0] A0 ro — 24-bit sign extended accumulator0 status
0x40340414 UAB_DC0_A1 — decimator0 accumulator 1
  [31:0] A1 ro — 24-bit sign extended accumulator1 status
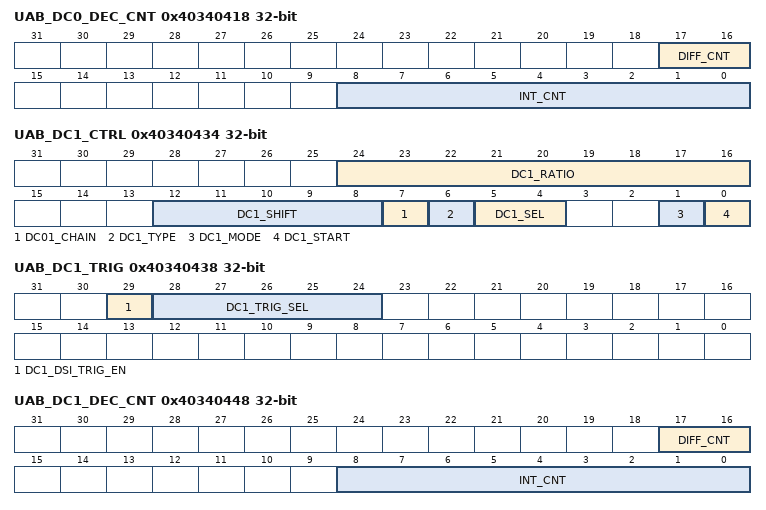
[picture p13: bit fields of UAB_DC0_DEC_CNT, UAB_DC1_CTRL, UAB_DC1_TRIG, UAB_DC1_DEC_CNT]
0x40340418 UAB_DC0_DEC_CNT — decimator0 decimation counter
  [17:16] DIFF_CNT ro — differentiation down counter
  [8:0] INT_CNT ro — integration/decimation down counter
0x4034041C UAB_DC0_TMP — decimator0 temporary value for differentiator
  [31:0] TMP ro — 24-bit sign extended differentiator temporary value status
0x40340420 UAB_DC0_D0 — decimator0 differentiator 0
  [31:0] D0 ro — 24-bit sign extended differentiator 0 status
0x40340424 UAB_DC0_D1 — decimator0 differentiator 1
  [31:0] D1 ro — 24-bit sign extended differentiator 1 status
0x40340428 UAB_DC0_RES — decimator0 result
  [31:0] RES ro — 24-bit sign extended result
0x40340434 UAB_DC1_CTRL — decimator1 control
  [24:16] DC1_RATIO — decimation ratio = DC1_RATIO+1, range 1..512
  [12:8] DC1_SHIFT — shift the result right by specified amount, legal range 0..16
  [7] DC01_CHAIN — Chain decimator0 and decimator1
  [6] DC1_TYPE — decimator type (filter order)
    0=SINC1 (first order); 1=SINC2 (second order)
  [5:4] DC1_SEL — Source select
    values as UAB_DC0_CTRL.DC0_SEL
  [1] DC1_MODE — Operation mode?0: Incremental (one-shot) operation?1: Continuous operation
  [0] DC1_START — Start decimator, in incremental mode, this bit is cleared by HW when done. If DSI trigger enable is set then only start after a DSI trigger.
0x40340438 UAB_DC1_TRIG — decimator1 trigger control
  [29] DC1_DSI_TRIG_EN — Decimator DSI trigger input Enable?0: Ignore decimator DSI trigger input?1: Wait for positive edge on selected DSI trigger input
  [28:24] DC1_TRIG_SEL — Trigger select?0=UAB0 half 0 trigger output?1=UAB0 half 1 trigger output?2=UAB1 half 0 trigger output?3=UAB1 half 1 trigger output?4=UAB2 half 0 trigger output?5=UAB2 half 1 trigger output?6=UAB3 half 0 trigger output?7=UAB3 half 1 trigger output?8-30 = generic trigger inputs 0-22?31=SAR trigger output?For PASS4B only values 0-1 and 8-11 and 31 are legal.
0x4034043C UAB_DC1_OVR — decimator 1 overflow control
  [4:0] DC1_OVR_CORR_LOC — Bit location for overflow correction. This should be set to FILTER_ORDER*log2(DC1_RATIO)
0x40340440 UAB_DC1_A0 — decimator1 accumulator 0
  [31:0] A0 ro — 27-bit sign extended accumulator0 status
0x40340444 UAB_DC1_A1 — decimator1 accumulator 1
  [31:0] A1 ro — 27-bit sign extended accumulator1 status
0x40340448 UAB_DC1_DEC_CNT — decimator1 decimation counter
  fields as UAB_DC0_DEC_CNT
0x4034044C UAB_DC1_TMP — decimator1 temporary value for differentiator
  [31:0] TMP ro — 27-bit sign extended differentiator temporary value status
0x40340450 UAB_DC1_D0 — decimator1 differentiator 0
  [31:0] D0 ro — 27-bit sign extended differentiator 0 status
0x40340454 UAB_DC1_D1 — decimator1 differentiator 1
  [31:0] D1 ro — 27-bit sign extended differentiator 1 status
0x40340458 UAB_DC1_RES — decimator1 result
  [31:0] RES ro — 27-bit sign extended result
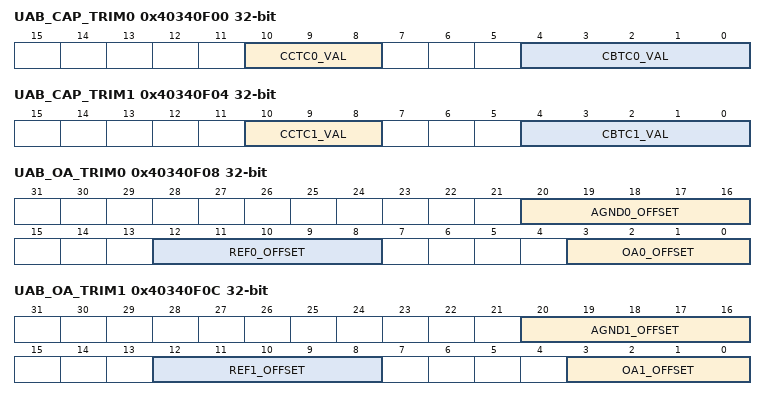
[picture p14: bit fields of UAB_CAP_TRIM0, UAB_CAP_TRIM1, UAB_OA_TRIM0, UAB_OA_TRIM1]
0x40340F00 UAB_CAP_TRIM0 — Trim for attenuation cap half0
  [10:8] CCTC0_VAL — Cap C Trim 0 Value?Do not measure value, instead use same value as for CBTC0_VAL
  [4:0] CBTC0_VAL — Cap B Trim 0 Value?Trim attenuation cap in branch B for DAC correctness
0x40340F04 UAB_CAP_TRIM1 — Trim for attenuation cap half1
  [10:8] CCTC1_VAL — Cap C Trim 1 Value?Do not measure value, instead use same value as for CBTC1_VAL
  [4:0] CBTC1_VAL — Cap B Trim 1 Value?Trim attenuation cap in branch B for DAC correctness
0x40340F08 UAB_OA_TRIM0 — Trim for opamp and buffers half0
  [20:16] AGND0_OFFSET — Agnd buffer offset trim
  [12:8] REF0_OFFSET — Reference buffer offset trim
  [3:0] OA0_OFFSET — Opamp offset trim
0x40340F0C UAB_OA_TRIM1 — Trim for opamp and buffers half1
  [20:16] AGND1_OFFSET — Agnd buffer offset trim
  [12:8] REF1_OFFSET — Reference buffer offset trim
  [3:0] OA1_OFFSET — Opamp offset trim
